# ESP32-C6 register map
Vendor: ESPRESSIF SYSTEMS (SHANGHAI) CO., LTD.; Series: ESP32 C-Series; File version: 12
CPU: RV32IMAC r0p0, little endian, no MPU, no FPU, 0 interrupt priority bits
Address unit: 32 bits
Registers are 32-bit, read-write, reset 0x0 unless marked. A register's access mark holds for its fields unless they carry their own. Offsets are from the block's base; [hi:lo] are bit positions; {n}, {i} and the like mark numbered series.

## I2C_ANA_MST — I2C_ANA_MST Peripheral
Base 0x600AF800
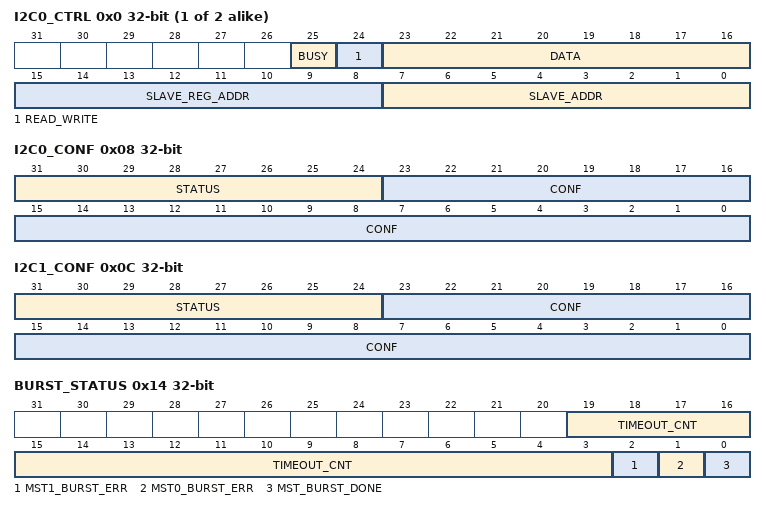
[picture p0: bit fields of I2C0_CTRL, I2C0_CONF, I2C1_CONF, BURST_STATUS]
{0x0+4i} I2C{i}_CTRL (i=0..1) — I2C{i}_CTRL register
  [25] BUSY ro — Represents whether I2C0 is currently transferring data
  [24] READ_WRITE — Configures the read/write operation
  [23:16] DATA — Configures the transmitted data
  [15:8] SLAVE_REG_ADDR — Configures the slave register address
  [7:0] SLAVE_ADDR — Configures the slave address
0x08 I2C0_CONF
  [31:24] STATUS ro — ?
  [23:0] CONF — ?
0x0C I2C1_CONF
  [31:24] STATUS ro — ?
  [23:0] CONF — ?
0x10 BURST_CONF
  [31:0] BURST_CTRL — ?
0x14 BURST_STATUS
  [19:3] TIMEOUT_CNT ro — ?
  [2] MST1_BURST_ERR ro — ?
  [1] MST0_BURST_ERR ro — ?
  [0] MST_BURST_DONE ro — ?
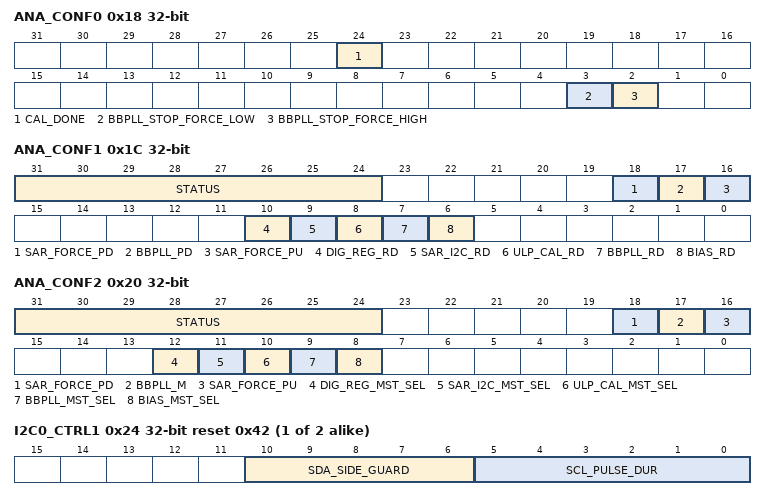
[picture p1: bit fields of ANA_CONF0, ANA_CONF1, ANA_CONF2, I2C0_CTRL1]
0x18 ANA_CONF0
  [24] CAL_DONE ro — BBPLL calibration done
  [3] BBPLL_STOP_FORCE_LOW — ?
  [2] BBPLL_STOP_FORCE_HIGH — ?
0x1C ANA_CONF1
  [31:24] STATUS ro — ?
  [18] SAR_FORCE_PD — ?
  [17] BBPLL_PD — Clear to enable BBPLL
  [16] SAR_FORCE_PU — ?
  [10] DIG_REG_RD — Clear to select
  [9] SAR_I2C_RD — Clear to select
  [8] ULP_CAL_RD — Clear to select
  [7] BBPLL_RD — Clear to select
  [6] BIAS_RD — Clear to select
0x20 ANA_CONF2
  [31:24] STATUS ro — ?
  [18] SAR_FORCE_PD — ?
  [17] BBPLL_M — Clear to enable BBPLL
  [16] SAR_FORCE_PU — ?
  [12] DIG_REG_MST_SEL — Configures which I2C master the following analog modules uses. If the corresponding bit is set to 1, I2C0 master is used for communication; if set to 0, I2C1 master is used.
  [11] SAR_I2C_MST_SEL — Configures which I2C master the following analog modules uses. If the corresponding bit is set to 1, I2C0 master is used for communication; if set to 0, I2C1 master is used.
  [10] ULP_CAL_MST_SEL — Configures which I2C master the following analog modules uses. If the corresponding bit is set to 1, I2C0 master is used for communication; if set to 0, I2C1 master is used.
  [9] BBPLL_MST_SEL — Configures which I2C master the following analog modules uses. If the corresponding bit is set to 1, I2C0 master is used for communication; if set to 0, I2C1 master is used.
  [8] BIAS_MST_SEL — Configures which I2C master the following analog modules uses. If the corresponding bit is set to 1, I2C0 master is used for communication; if set to 0, I2C1 master is used.
{0x24+4i} I2C{i}_CTRL1 (i=0..1) reset 0x42 — I2C{i}_CTRL1 register
  [10:6] SDA_SIDE_GUARD — Configures the duration of the low-level period of the SCL driven by I2C0
  [5:0] SCL_PULSE_DUR — Configures the duration of the high-level period of the SCL driven by I2C0
0x34 DATE

## MODEM_SYSCON — MODEM_SYSCON Peripheral
Base 0x600A9800
0x00 TEST_CONF
  [0] CLK_EN
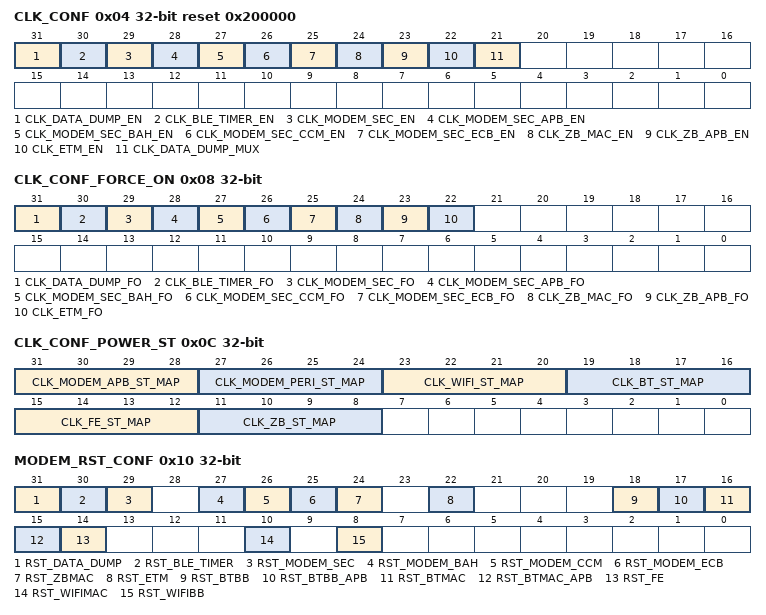
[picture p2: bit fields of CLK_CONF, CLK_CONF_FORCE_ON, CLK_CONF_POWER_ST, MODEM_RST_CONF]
0x04 CLK_CONF reset 0x200000
  [31] CLK_DATA_DUMP_EN, [30] CLK_BLE_TIMER_EN, [29] CLK_MODEM_SEC_EN, [28] CLK_MODEM_SEC_APB_EN, [27] CLK_MODEM_SEC_BAH_EN, [26] CLK_MODEM_SEC_CCM_EN, [25] CLK_MODEM_SEC_ECB_EN, [24] CLK_ZB_MAC_EN, [23] CLK_ZB_APB_EN, [22] CLK_ETM_EN, [21] CLK_DATA_DUMP_MUX
0x08 CLK_CONF_FORCE_ON
  [31] CLK_DATA_DUMP_FO, [30] CLK_BLE_TIMER_FO, [29] CLK_MODEM_SEC_FO, [28] CLK_MODEM_SEC_APB_FO, [27] CLK_MODEM_SEC_BAH_FO, [26] CLK_MODEM_SEC_CCM_FO, [25] CLK_MODEM_SEC_ECB_FO, [24] CLK_ZB_MAC_FO, [23] CLK_ZB_APB_FO, [22] CLK_ETM_FO
0x0C CLK_CONF_POWER_ST
  [31:28] CLK_MODEM_APB_ST_MAP, [27:24] CLK_MODEM_PERI_ST_MAP, [23:20] CLK_WIFI_ST_MAP, [19:16] CLK_BT_ST_MAP, [15:12] CLK_FE_ST_MAP, [11:8] CLK_ZB_ST_MAP
0x10 MODEM_RST_CONF
  [31] RST_DATA_DUMP, [30] RST_BLE_TIMER, [29] RST_MODEM_SEC, [27] RST_MODEM_BAH, [26] RST_MODEM_CCM, [25] RST_MODEM_ECB, [24] RST_ZBMAC, [22] RST_ETM, [18] RST_BTBB, [17] RST_BTBB_APB, [16] RST_BTMAC, [15] RST_BTMAC_APB, [14] RST_FE, [10] RST_WIFIMAC, [8] RST_WIFIBB
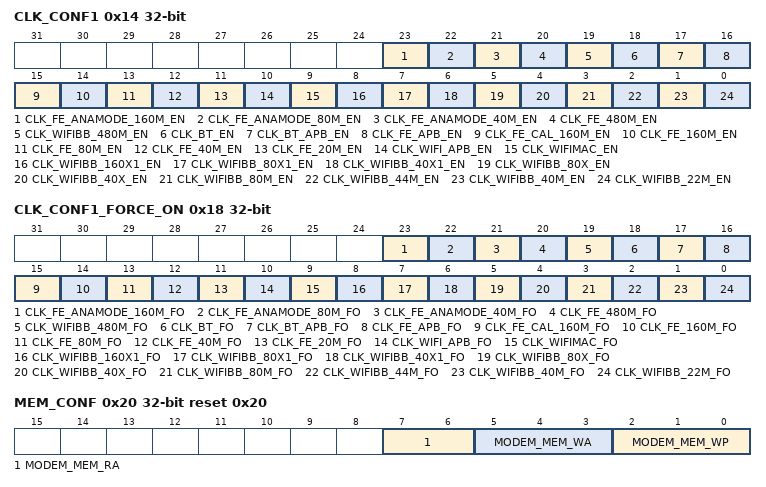
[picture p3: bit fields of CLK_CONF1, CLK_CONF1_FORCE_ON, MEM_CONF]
0x14 CLK_CONF1
  [23] CLK_FE_ANAMODE_160M_EN, [22] CLK_FE_ANAMODE_80M_EN, [21] CLK_FE_ANAMODE_40M_EN, [20] CLK_FE_480M_EN, [19] CLK_WIFIBB_480M_EN, [18] CLK_BT_EN, [17] CLK_BT_APB_EN, [16] CLK_FE_APB_EN, [15] CLK_FE_CAL_160M_EN, [14] CLK_FE_160M_EN, [13] CLK_FE_80M_EN, [12] CLK_FE_40M_EN, [11] CLK_FE_20M_EN, [10] CLK_WIFI_APB_EN, [9] CLK_WIFIMAC_EN, [8] CLK_WIFIBB_160X1_EN, [7] CLK_WIFIBB_80X1_EN, [6] CLK_WIFIBB_40X1_EN, [5] CLK_WIFIBB_80X_EN, [4] CLK_WIFIBB_40X_EN, [3] CLK_WIFIBB_80M_EN, [2] CLK_WIFIBB_44M_EN, [1] CLK_WIFIBB_40M_EN, [0] CLK_WIFIBB_22M_EN
0x18 CLK_CONF1_FORCE_ON
  [23] CLK_FE_ANAMODE_160M_FO, [22] CLK_FE_ANAMODE_80M_FO, [21] CLK_FE_ANAMODE_40M_FO, [20] CLK_FE_480M_FO, [19] CLK_WIFIBB_480M_FO, [18] CLK_BT_FO, [17] CLK_BT_APB_FO, [16] CLK_FE_APB_FO, [15] CLK_FE_CAL_160M_FO, [14] CLK_FE_160M_FO, [13] CLK_FE_80M_FO, [12] CLK_FE_40M_FO, [11] CLK_FE_20M_FO, [10] CLK_WIFI_APB_FO, [9] CLK_WIFIMAC_FO, [8] CLK_WIFIBB_160X1_FO, [7] CLK_WIFIBB_80X1_FO, [6] CLK_WIFIBB_40X1_FO, [5] CLK_WIFIBB_80X_FO, [4] CLK_WIFIBB_40X_FO, [3] CLK_WIFIBB_80M_FO, [2] CLK_WIFIBB_44M_FO, [1] CLK_WIFIBB_40M_FO, [0] CLK_WIFIBB_22M_FO
0x1C WIFI_BB_CFG
0x20 MEM_CONF reset 0x20
  [7:6] MODEM_MEM_RA, [5:3] MODEM_MEM_WA, [2:0] MODEM_MEM_WP
0x24 DATE — AES version control register
